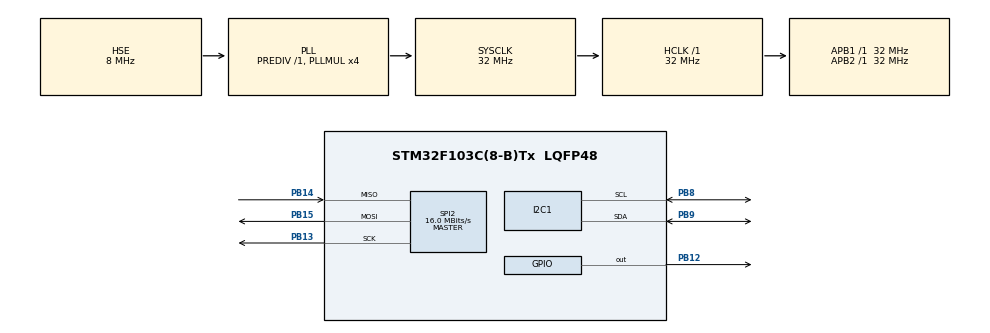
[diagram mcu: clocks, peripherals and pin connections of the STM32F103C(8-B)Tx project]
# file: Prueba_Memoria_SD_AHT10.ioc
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FATFS._CODE_PAGE=1
Mcu.Family=STM32F1
Mcu.Name=STM32F103C(8-B)Tx
Mcu.Package=LQFP48
NVIC.PriorityGroup=NVIC_PRIORITYGROUP_4
NVIC.TIM2_IRQn=true\:0\:0\:false\:false\:true\:true\:true\:true
PA13.Mode=Serial_Wire
PA13.Signal=SYS_JTMS-SWDIO
PA14.Mode=Serial_Wire
PA14.Signal=SYS_JTCK-SWCLK
PB12.Signal=GPIO_Output
PB13.Mode=Full_Duplex_Master
PB13.Signal=SPI2_SCK
PB14.Mode=Full_Duplex_Master
PB14.Signal=SPI2_MISO
PB15.Mode=Full_Duplex_Master
PB15.Signal=SPI2_MOSI
PB8.Mode=I2C
PB8.Signal=I2C1_SCL
PB9.Mode=I2C
PB9.Signal=I2C1_SDA
PD0-OSC_IN.Mode=HSE-External-Oscillator
PD0-OSC_IN.Signal=RCC_OSC_IN
PD1-OSC_OUT.Mode=HSE-External-Oscillator
PD1-OSC_OUT.Signal=RCC_OSC_OUT
ProjectManager.HeapSize=0x200
ProjectManager.StackSize=0x400
ProjectManager.TargetToolchain=STM32CubeIDE
RCC.AHBFreq_Value=32000000
RCC.APB1Freq_Value=32000000
RCC.APB1TimFreq_Value=32000000
RCC.APB2Freq_Value=32000000
RCC.APB2TimFreq_Value=32000000
RCC.HCLKFreq_Value=32000000
RCC.PLLMUL=RCC_PLL_MUL4
RCC.PLLSourceVirtual=RCC_PLLSOURCE_HSE
RCC.SYSCLKFreq_VALUE=32000000
RCC.SYSCLKSource=RCC_SYSCLKSOURCE_PLLCLK
RCC.USBFreq_Value=32000000
RTC.Date=12
RTC.Hours=22
RTC.Minutes=57
RTC.Month=RTC_MONTH_OCTOBER
RTC.WeekDay=RTC_WEEKDAY_WEDNESDAY
RTC.Year=22
SPI2.CalculateBaudRate=16.0 MBits/s
SPI2.Direction=SPI_DIRECTION_2LINES
SPI2.Mode=SPI_MODE_MASTER
SPI2.VirtualType=VM_MASTER
TIM2.Period=50000
TIM2.Prescaler=3200
VP_FATFS_VS_Generic.Mode=User_defined
VP_RTC_VS_RTC_Activate.Mode=RTC_Enabled
VP_RTC_VS_RTC_Calendar.Mode=RTC_Calendar
VP_TIM2_VS_ClockSourceINT.Mode=Internal
board=custom

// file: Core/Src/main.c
/* USER CODE BEGIN Header */
/**
  ******************************************************************************
  * @file           : main.c
  * @brief          : Main program body
  ******************************************************************************
  * @attention
  *
  * Copyright (c) 2022 STMicroelectronics.
  * All rights reserved.
  *
  * This software is licensed under terms that can be found in the LICENSE file
  * in the root directory of this software component.
  * If no LICENSE file comes with this software, it is provided AS-IS.
  *
  ******************************************************************************
  */
/* USER CODE END Header */
#include "main.h"
#include "fatfs.h"

/* USER CODE BEGIN Includes */
#include "SPISD.h"
#include "stdio.h"
#include "string.h"
#include "AHT10.h"
/* USER CODE END Includes */

/* USER CODE BEGIN PD */
/*#define I2C_ADDRESS_AHT10 0x38
#define TRIGGER_MEASUREMENT 0xAC
#define DATA0 0x33
#define DATA1 0x00 */
/* USER CODE END PD */

I2C_HandleTypeDef hi2c1;

RTC_HandleTypeDef hrtc;

SPI_HandleTypeDef hspi2;

TIM_HandleTypeDef htim2;

/* USER CODE BEGIN PV */
SPISD spisd;
SPISD *mainSD = &spisd;
uint8_t Sector0[516];
RTC_HandleTypeDef *pRTC;

//float tcelsius, hr; // Temperatura (en °C) y humedad relativa (%)
_Bool flag_muestras=0; // Variable tipo bandera que se activa cuando interrumpe el timer TIM2 (cada 5 s)

/* USER CODE END PV */

void SystemClock_Config(void);
static void MX_GPIO_Init(void);
static void MX_TIM2_Init(void);
static void MX_RTC_Init(void);
static void MX_I2C1_Init(void);
static void MX_SPI2_Init(void);
/* USER CODE BEGIN PFP */
void AHT10_Read(void);
/* USER CODE END PFP */

/* USER CODE BEGIN 0 */

void HAL_TIM_PeriodElapsedCallback(TIM_HandleTypeDef *htim){

	flag_muestras=1;
}

/* Esta función permite leer datos de temperatura y humedad del sensor AHT10. Para que el sensor
 * comience con las mediciones, es necesario enviar un comando de disparo de medición (trigger
 * measurement) junto con dos bytes de datos DATA0 y DATA1. El sensor tardará un tiempo en
 * realizar la medición y recolectar los datos (más de 75 ms). Transcurrido ese tiempo,
 * los datos de temperatura y humedad son recibidos, repartidos en 5 bytes, junto con un byte que
 * indica el estado del sensor
//void AHT10_Read(){

	 Definimos el comando de disparo de medición y lo enviamos a través de I2C1
	uint8_t triggerdata[3] = {TRIGGER_MEASUREMENT,DATA0,DATA1};
	HAL_I2C_Master_Transmit(&hi2c1, I2C_ADDRESS_AHT10<<1, triggerdata, sizeof(triggerdata), 100);
	HAL_Delay(100); // Demora de 100 ms para que el sensor recolecte los datos

	 Debemos recibir el dato de temperatura y humedad y guardarlo en la variable correspondiente.
	 * Para ello debemos tener en cuenta que la trama de comunicación serie recibida desde el sensor
	 * constará de 6 bytes:
	 * - BYTE 0: Byte de estado (status) que indica el estado del sensor
	 * - BYTE 1: Dato de humedad
	 * - BYTE 2: Dato de humedad
	 * - BYTE 3: Dato de humedad (4 bits más significativos) y dato de temp. (4 bits menos significativos)
	 * - BYTE 4: Dato de temperatura
	 * - BYTE 5: Dato de temperatura
	 * Tanto el dato de temperatura como el dato de humedad ocupan 20 bits.

	uint32_t temp, hum; // Variables para guardar los datos recibidos de temperatura y humedad
	uint8_t bufdata[6]; // Buffer para guardar los datos recibidos desde el sensor
	if(HAL_I2C_Master_Receive(&hi2c1, I2C_ADDRESS_AHT10<<1, bufdata, sizeof(bufdata), 100) == HAL_OK){

		 Obtenemos el dato de humedad y lo guardamos en la variable hum
		hum=bufdata[1]<<8; // Desplazamos el BYTE 1 8 posiciones hacia la izquierda
		hum|=bufdata[2]; // Concatenamos el BYTE 2 usando el operador lógico OR
		hum<<=4; // Desplazamos el contenido de hum 4 pos. hacia la izq.
		hum|=(bufdata[3] & 0xF0)>>4; // Concanetamos los 4 bits más significativos del BYTE 3 usando una máscara y el operador OR

		 Obtenemos el dato de temperatura y lo guardamos en la variable temp
		temp=(bufdata[3] & 0x0F)<<8; // Obtenemos los 4 bits menos significativos del BYTE3 usando una máscara y los desplazamos 8 pos. hacia la der.
		temp|=bufdata[4]; // Concatenamos el BYTE 4 usando el operador OR
		temp<<=8; // Desplazamos el contenido de temp 8 pos. hacia la der.
		temp|=bufdata[5]; // Concatenamos el BYTE 5 usando el operador OR

		 Realizamos la conversión del dato de temperatura recibido desde la línea SDA a temperatura
		 * expresada en grados celsius (°C) utilizando la fórmula provista por la hoja de datos
		 * T(°C)=(temp/2^20)*200-50
		 * Como 2^20=1.048.576 --> T(°C)=(temp/1048576)*200-50
		tcelsius=(temp/1048576.0)*200.0-50.0;

		 Realizamos la conversión del dato de humedad recibido desde la línea SDA a humedad
		 * relativa expresada en porcentaje, utilizando la fórmula provista por la hoja de datos
		 * HR=(hum/2^20)*100
		 * Como 2^20=1.048.576 --> HR=(hum/1048576)*100
		hr=(hum/1048576.0)*100.0;
	}
}*/
/* USER CODE END 0 */

int main(void)
{

  /* MCU Configuration--------------------------------------------------------*/

  /* Reset of all peripherals, Initializes the Flash interface and the Systick. */
  HAL_Init();

  /* Configure the system clock */
  SystemClock_Config();

  /* USER CODE BEGIN SysInit */
  /* Definimos los campos de la estructura de tipo SPISD, la cual contiene información sobre la memoria SD */
  spisd.FSM=Encendido;
  spisd.csPuerto = GPIOB;
  spisd.csPin = GPIO_PIN_12;
  spisd.puertoSPI = &hspi2;
  spisd.sectorAddressing=1; //Asumimos SDHC (+2GB)
  spisd.hrtc = &hrtc;
  /* USER CODE END SysInit */

  /* Initialize all configured peripherals */
  MX_GPIO_Init();
  MX_TIM2_Init();
  MX_FATFS_Init();
  MX_RTC_Init();
  MX_I2C1_Init();
  MX_SPI2_Init();
  /* USER CODE BEGIN 2 */
  uint8_t buf[10];

  //SPISD_DetectarSD(&spisd);
  f_mount(&USERFatFS,USERPath,0); // Las variables &USERFatFS y USERPath son creadas automáticamente por el File system
  f_open(&USERFile,"Data.txt",FA_CREATE_ALWAYS | FA_WRITE);
  uint32_t output;

  /* USER CODE END 2 */

  /* Infinite loop */
  while (1)
  {

    /* USER CODE BEGIN 3 */
	  if(flag_muestras==1){
		  flag_muestras=0;
		  AHT10_Read();
		  sprintf((char*)buf,"%2.1f %2.1f\n",tcelsius,hr);
		  if (f_write(&USERFile,buf,strlen((const char*)buf),(void*)&output)==FR_OK)
		  {
			  if (f_sync(&USERFile)==FR_OK){
				  f_close(&USERFile);
			  }

		  }
	  }
  }
  /* USER CODE END 3 */
}

void SystemClock_Config(void)
{
  RCC_OscInitTypeDef RCC_OscInitStruct = {0};
  RCC_ClkInitTypeDef RCC_ClkInitStruct = {0};
  RCC_PeriphCLKInitTypeDef PeriphClkInit = {0};

  /** Initializes the RCC Oscillators according to the specified parameters
  * in the RCC_OscInitTypeDef structure.
  */
  RCC_OscInitStruct.OscillatorType = RCC_OSCILLATORTYPE_LSI|RCC_OSCILLATORTYPE_HSE;
  RCC_OscInitStruct.HSEState = RCC_HSE_ON;
  RCC_OscInitStruct.HSEPredivValue = RCC_HSE_PREDIV_DIV1;
  RCC_OscInitStruct.HSIState = RCC_HSI_ON;
  RCC_OscInitStruct.LSIState = RCC_LSI_ON;
  RCC_OscInitStruct.PLL.PLLState = RCC_PLL_ON;
  RCC_OscInitStruct.PLL.PLLSource = RCC_PLLSOURCE_HSE;
  RCC_OscInitStruct.PLL.PLLMUL = RCC_PLL_MUL4;
  if (HAL_RCC_OscConfig(&RCC_OscInitStruct) != HAL_OK)
  {
    Error_Handler();
  }

  /** Initializes the CPU, AHB and APB buses clocks
  */
  RCC_ClkInitStruct.ClockType = RCC_CLOCKTYPE_HCLK|RCC_CLOCKTYPE_SYSCLK
                              |RCC_CLOCKTYPE_PCLK1|RCC_CLOCKTYPE_PCLK2;
  RCC_ClkInitStruct.SYSCLKSource = RCC_SYSCLKSOURCE_PLLCLK;
  RCC_ClkInitStruct.AHBCLKDivider = RCC_SYSCLK_DIV1;
  RCC_ClkInitStruct.APB1CLKDivider = RCC_HCLK_DIV1;
  RCC_ClkInitStruct.APB2CLKDivider = RCC_HCLK_DIV1;

  if (HAL_RCC_ClockConfig(&RCC_ClkInitStruct, FLASH_LATENCY_1) != HAL_OK)
  {
    Error_Handler();
  }
  PeriphClkInit.PeriphClockSelection = RCC_PERIPHCLK_RTC;
  PeriphClkInit.RTCClockSelection = RCC_RTCCLKSOURCE_LSI;
  if (HAL_RCCEx_PeriphCLKConfig(&PeriphClkInit) != HAL_OK)
  {
    Error_Handler();
  }
}

static void MX_I2C1_Init(void)
{

  hi2c1.Instance = I2C1;
  hi2c1.Init.ClockSpeed = 100000;
  hi2c1.Init.DutyCycle = I2C_DUTYCYCLE_2;
  hi2c1.Init.OwnAddress1 = 0;
  hi2c1.Init.AddressingMode = I2C_ADDRESSINGMODE_7BIT;
  hi2c1.Init.DualAddressMode = I2C_DUALADDRESS_DISABLE;
  hi2c1.Init.OwnAddress2 = 0;
  hi2c1.Init.GeneralCallMode = I2C_GENERALCALL_DISABLE;
  hi2c1.Init.NoStretchMode = I2C_NOSTRETCH_DISABLE;
  if (HAL_I2C_Init(&hi2c1) != HAL_OK)
  {
    Error_Handler();
  }

}

static void MX_RTC_Init(void)
{

  RTC_TimeTypeDef sTime = {0};
  RTC_DateTypeDef DateToUpdate = {0};

  /** Initialize RTC Only
  */
  hrtc.Instance = RTC;
  hrtc.Init.AsynchPrediv = RTC_AUTO_1_SECOND;
  hrtc.Init.OutPut = RTC_OUTPUTSOURCE_ALARM;
  if (HAL_RTC_Init(&hrtc) != HAL_OK)
  {
    Error_Handler();
  }

  /** Initialize RTC and set the Time and Date
  */
  sTime.Hours = 0x22;
  sTime.Minutes = 0x57;
  sTime.Seconds = 0x0;

  if (HAL_RTC_SetTime(&hrtc, &sTime, RTC_FORMAT_BCD) != HAL_OK)
  {
    Error_Handler();
  }
  DateToUpdate.WeekDay = RTC_WEEKDAY_WEDNESDAY;
  DateToUpdate.Month = RTC_MONTH_OCTOBER;
  DateToUpdate.Date = 0x12;
  DateToUpdate.Year = 0x22;

  if (HAL_RTC_SetDate(&hrtc, &DateToUpdate, RTC_FORMAT_BCD) != HAL_OK)
  {
    Error_Handler();
  }

}

static void MX_SPI2_Init(void)
{

  /* SPI2 parameter configuration*/
  hspi2.Instance = SPI2;
  hspi2.Init.Mode = SPI_MODE_MASTER;
  hspi2.Init.Direction = SPI_DIRECTION_2LINES;
  hspi2.Init.DataSize = SPI_DATASIZE_8BIT;
  hspi2.Init.CLKPolarity = SPI_POLARITY_LOW;
  hspi2.Init.CLKPhase = SPI_PHASE_1EDGE;
  hspi2.Init.NSS = SPI_NSS_SOFT;
  hspi2.Init.BaudRatePrescaler = SPI_BAUDRATEPRESCALER_2;
  hspi2.Init.FirstBit = SPI_FIRSTBIT_MSB;
  hspi2.Init.TIMode = SPI_TIMODE_DISABLE;
  hspi2.Init.CRCCalculation = SPI_CRCCALCULATION_DISABLE;
  hspi2.Init.CRCPolynomial = 10;
  if (HAL_SPI_Init(&hspi2) != HAL_OK)
  {
    Error_Handler();
  }

}

static void MX_TIM2_Init(void)
{

  TIM_ClockConfigTypeDef sClockSourceConfig = {0};
  TIM_MasterConfigTypeDef sMasterConfig = {0};

  htim2.Instance = TIM2;
  htim2.Init.Prescaler = 3200;
  htim2.Init.CounterMode = TIM_COUNTERMODE_UP;
  htim2.Init.Period = 50000;
  htim2.Init.ClockDivision = TIM_CLOCKDIVISION_DIV1;
  htim2.Init.AutoReloadPreload = TIM_AUTORELOAD_PRELOAD_DISABLE;
  if (HAL_TIM_Base_Init(&htim2) != HAL_OK)
  {
    Error_Handler();
  }
  sClockSourceConfig.ClockSource = TIM_CLOCKSOURCE_INTERNAL;
  if (HAL_TIM_ConfigClockSource(&htim2, &sClockSourceConfig) != HAL_OK)
  {
    Error_Handler();
  }
  sMasterConfig.MasterOutputTrigger = TIM_TRGO_RESET;
  sMasterConfig.MasterSlaveMode = TIM_MASTERSLAVEMODE_DISABLE;
  if (HAL_TIMEx_MasterConfigSynchronization(&htim2, &sMasterConfig) != HAL_OK)
  {
    Error_Handler();
  }
  /* USER CODE BEGIN TIM2_Init 2 */
  HAL_TIM_Base_Start_IT(&htim2); // Inicializamos el TIM2 en modo base de tiempos
  /* USER CODE END TIM2_Init 2 */

}

static void MX_GPIO_Init(void)
{
  GPIO_InitTypeDef GPIO_InitStruct = {0};

  /* GPIO Ports Clock Enable */
  __HAL_RCC_GPIOD_CLK_ENABLE();
  __HAL_RCC_GPIOB_CLK_ENABLE();
  __HAL_RCC_GPIOA_CLK_ENABLE();

  /*Configure GPIO pin Output Level */
  HAL_GPIO_WritePin(GPIOB, GPIO_PIN_12, GPIO_PIN_RESET);

  /*Configure GPIO pin : PB12 */
  GPIO_InitStruct.Pin = GPIO_PIN_12;
  GPIO_InitStruct.Mode = GPIO_MODE_OUTPUT_PP;
  GPIO_InitStruct.Pull = GPIO_NOPULL;
  GPIO_InitStruct.Speed = GPIO_SPEED_FREQ_LOW;
  HAL_GPIO_Init(GPIOB, &GPIO_InitStruct);

}

void Error_Handler(void)
{
  __disable_irq();
  while (1)
  {
  }
}
